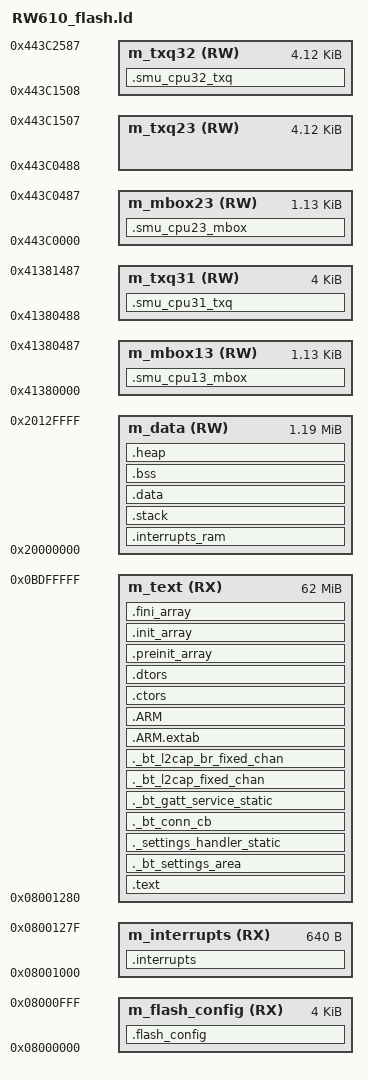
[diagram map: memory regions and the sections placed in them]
/*
** ###################################################################
**     Processors:          RW612ETA2I
**                          RW612HNA2I
**                          RW612UKA2I
**
**     Compiler:            GNU C Compiler
**     Reference manual:    MIMXRW685 User manual Rev. 0.95 11 November 2019
**     Version:             rev. 1.0, 2021-03-16
**     Build:               b220521
**
**     Abstract:
**         Linker file for the GNU C Compiler
**
**     Copyright 2016 Freescale Semiconductor, Inc.
**     Copyright 2016-2024 NXP
**     All rights reserved.
**
**     SPDX-License-Identifier: BSD-3-Clause
**
**     http:                 www.nxp.com
**     mail:                 support@nxp.com
**
** ###################################################################
*/



/* Entry Point */
ENTRY(Reset_Handler)

HEAP_SIZE  = DEFINED(__heap_size__)  ? __heap_size__  : 0x0400;
STACK_SIZE = DEFINED(__stack_size__) ? __stack_size__ : 0x0400;
M_VECTOR_RAM_SIZE = DEFINED(__ram_vector_table__) ? 0x00000280 : 0;

LITTLEFS_REGION_SIZE = 0x00200000;

m_text_start         = 0x08001280;
m_text_size          = 0x03FFED80 - LITTLEFS_REGION_SIZE;

/* Specify the memory areas */
MEMORY
{
  m_flash_config        (RX)  : ORIGIN = 0x08000000, LENGTH = 0x00001000
  m_interrupts          (RX)  : ORIGIN = 0x08001000, LENGTH = 0x00000280
  m_text                (RX)  : ORIGIN = m_text_start, LENGTH = m_text_size
  m_data                (RW)  : ORIGIN = 0x20000000, LENGTH = 0x00130000
  m_mbox13              (RW) : ORIGIN = 0x41380000, LENGTH = 0x00000488
  m_txq31               (RW) : ORIGIN = 0x41380488, LENGTH = 0x00001000
  m_mbox23              (RW) : ORIGIN = 0x443C0000, LENGTH = 0x00000488
  m_txq23               (RW) : ORIGIN = 0x443C0488, LENGTH = 0x00001080
  m_txq32               (RW) : ORIGIN = 0x443C1508, LENGTH = 0x00001080
}

/* NOTE: The last LITTLEFS_REGION_SIZE Flash( in range (m_text_start + m_text_size) ~ (m_text_start + m_text_size + LITTLEFS_REGION_SIZE -1)) is reserved for litteFS data */

/*** littleFS configuration Start ***/
EDGEFAST_BT_LITTLEFS_STORAGE_START_ADDRESS = m_text_start + m_text_size;
EDGEFAST_BT_LITTLEFS_STORAGE_SECTOR_SIZE   = 0x1000;  /* 4k flash sector size */
EDGEFAST_BT_LITTLEFS_STORAGE_MAX_SECTORS   = LITTLEFS_REGION_SIZE / EDGEFAST_BT_LITTLEFS_STORAGE_SECTOR_SIZE;
/*** littleFS configuration End ***/

/* Define output sections */
SECTIONS
{
  .flash_config :
  {
    . = ALIGN(4);
    FILL(0xFF)
    . = 0x400;
    __FLASH_BASE = .;
    KEEP(* (.flash_conf))     /* flash config section */
    . = 0x1000;
  } > m_flash_config

  /* The startup code goes first into internal ram */
  .interrupts :
  {
    . = ALIGN(4);
    __VECTOR_TABLE = .;
    __Vectors = .;
    KEEP(*(.isr_vector))     /* Startup code */
    FILL(0x00)
    . = 0x280;
  } > m_interrupts

  /* The program code and other data goes into internal ram */
  .text :
  {
    . = ALIGN(4);
    *(EXCLUDE_FILE(
        /* Exclude flash and frequently executed functions from XIP */
        */fsl_adapter_flexspi_nor_flash.c.obj
        */mflash_drv.c.obj
        */fsl_flexspi.c.obj
    ) .text)                 /* .text sections (code) */
    *(EXCLUDE_FILE(
        /* Exclude flash and frequently executed functions from XIP */
        */fsl_adapter_flexspi_nor_flash.c.obj
        */mflash_drv.c.obj
        */fsl_flexspi.c.obj
    ) .text*)                /* .text* sections (code) */
    *(.rodata)               /* .rodata sections (constants, strings, etc.) */
    *(.rodata*)              /* .rodata* sections (constants, strings, etc.) */
    *(.glue_7)               /* glue arm to thumb code */
    *(.glue_7t)              /* glue thumb to arm code */
    *(.eh_frame)
    KEEP (*(.init))
    KEEP (*(.fini))
    . = ALIGN(4);
  } > m_text

  ._bt_settings_area :
  {
    . = ALIGN(4);
    _bt_settings_start = .;
    KEEP(*(SORT(._bt_settings.static.*)))
    _bt_settings_end = .;
    . = ALIGN(4);
  } > m_text

  ._settings_handler_static :
  {
    . = ALIGN(4);
    _settings_handler_static_list_start = .;
    KEEP(*(SORT(._settings_handler_static.static.*)))
    _settings_handler_static_list_end = .;
    . = ALIGN(4);
  } > m_text

  ._bt_conn_cb :
  {
    . = ALIGN(4);
    _bt_conn_cb_list_start = .;
    KEEP(*(SORT(._bt_conn_cb.static.*)))
    _bt_conn_cb_list_end = .;
    . = ALIGN(4);
  } > m_text

  ._bt_gatt_service_static :
  {
    . = ALIGN(4);
    _bt_gatt_service_static_list_start = .;
    KEEP(*(SORT(._bt_gatt_service_static.static.*)))
    _bt_gatt_service_static_list_end = .;
    . = ALIGN(4);
  } > m_text

  ._bt_l2cap_fixed_chan :
  {
    . = ALIGN(4);
    _bt_l2cap_fixed_chan_list_start = .;
    KEEP(*(SORT(._bt_l2cap_fixed_chan.static.*)))
    _bt_l2cap_fixed_chan_list_end = .;
    . = ALIGN(4);
  } > m_text

  ._bt_l2cap_br_fixed_chan :
  {
    . = ALIGN(4);
    _bt_l2cap_br_fixed_chan_list_start = .;
    KEEP(*(SORT(._bt_l2cap_br_fixed_chan.static.*)))
    _bt_l2cap_br_fixed_chan_list_end = .;
    . = ALIGN(4);
  } > m_text

  .ARM.extab :
  {
    *(.ARM.extab* .gnu.linkonce.armextab.*)
  } > m_text

  .ARM :
  {
    __exidx_start = .;
    *(.ARM.exidx*)
    __exidx_end = .;
  } > m_text

 .ctors :
  {
    __CTOR_LIST__ = .;
    /* gcc uses crtbegin.o to find the start of
       the constructors, so we make sure it is
       first.  Because this is a wildcard, it
       doesn't matter if the user does not
       actually link against crtbegin.o; the
       linker won't look for a file to match a
       wildcard.  The wildcard also means that it
       doesn't matter which directory crtbegin.o
       is in.  */
    KEEP (*crtbegin.o(.ctors))
    KEEP (*crtbegin?.o(.ctors))
    /* We don't want to include the .ctor section from
       from the crtend.o file until after the sorted ctors.
       The .ctor section from the crtend file contains the
       end of ctors marker and it must be last */
    KEEP (*(EXCLUDE_FILE(*crtend?.o *crtend.o) .ctors))
    KEEP (*(SORT(.ctors.*)))
    KEEP (*(.ctors))
    __CTOR_END__ = .;
  } > m_text

  .dtors :
  {
    __DTOR_LIST__ = .;
    KEEP (*crtbegin.o(.dtors))
    KEEP (*crtbegin?.o(.dtors))
    KEEP (*(EXCLUDE_FILE(*crtend?.o *crtend.o) .dtors))
    KEEP (*(SORT(.dtors.*)))
    KEEP (*(.dtors))
    __DTOR_END__ = .;
  } > m_text

  .preinit_array :
  {
    PROVIDE_HIDDEN (__preinit_array_start = .);
    KEEP (*(.preinit_array*))
    PROVIDE_HIDDEN (__preinit_array_end = .);
  } > m_text

  .init_array :
  {
    PROVIDE_HIDDEN (__init_array_start = .);
    KEEP (*(SORT(.init_array.*)))
    KEEP (*(.init_array*))
    PROVIDE_HIDDEN (__init_array_end = .);
  } > m_text

  .fini_array :
  {
    PROVIDE_HIDDEN (__fini_array_start = .);
    KEEP (*(SORT(.fini_array.*)))
    KEEP (*(.fini_array*))
    PROVIDE_HIDDEN (__fini_array_end = .);
  } > m_text

  __etext = .;    /* define a global symbol at end of code */
  __DATA_ROM = .; /* Symbol is used by startup for data initialization */

  .interrupts_ram :
  {
    . = ALIGN(4);
    __VECTOR_RAM__ = .;
    __interrupts_ram_start__ = .; /* Create a global symbol at data start */
    *(.m_interrupts_ram)     /* This is a user defined section */
    . += M_VECTOR_RAM_SIZE;
    . = ALIGN(4);
    __interrupts_ram_end__ = .; /* Define a global symbol at data end */
  } > m_data

  __VECTOR_RAM = DEFINED(__ram_vector_table__) ? __VECTOR_RAM__ : ORIGIN(m_interrupts);
  __RAM_VECTOR_TABLE_SIZE_BYTES = DEFINED(__ram_vector_table__) ? (__interrupts_ram_end__ - __interrupts_ram_start__) : 0x0;

  .stack :
  {
    . = ALIGN(8);
    __StackLimit = .;
    . += STACK_SIZE;
    __StackTop = .;
  } > m_data

  PROVIDE(__stack = __StackTop);

  .data : AT(__DATA_ROM)
  {
    . = ALIGN(4);
    __DATA_RAM = .;
    __data_start__ = .;      /* create a global symbol at data start */
    *(CodeQuickAccess)       /* CodeQuickAccess sections */
    *(DataQuickAccess)       /* DataQuickAccess sections */
    *(m_usb_dma_init_data)
    /* Explicit placement of flash and frequently executed functions in RAM */
    */fsl_adapter_flexspi_nor_flash.c.obj
    */mflash_drv.c.obj
    */fsl_flexspi.c.obj
    *(.data)                 /* .data sections */
    *(.data*)                /* .data* sections */
    KEEP(*(.jcr*))
    . = ALIGN(4);
    _k_mem_slab_list_start = .;
    KEEP(*(SORT(._k_mem_slab*)))
    _k_mem_slab_list_end = .;
    . = ALIGN(4);
    _net_buf_pool_list = .;
    KEEP(*(SORT(._net_buf_pool*)))
    . = ALIGN(4);
    __data_end__ = .;        /* define a global symbol at data end */
  } > m_data

  __DATA_END = __DATA_ROM + (__data_end__ - __data_start__);
  text_end = ORIGIN(m_text) + LENGTH(m_text);
  ASSERT(__DATA_END <= text_end, "region m_text overflowed with text and data")
  _image_size = __DATA_END - __VECTOR_TABLE;

  /* Uninitialized data section */
  .bss :
  {
    /* This is used by the startup in order to initialize the .bss section */
    . = ALIGN(4);
    __START_BSS = .;
    __bss_start__ = .;
    *(.bss)
    *(.bss*)
    *(COMMON)
    . = ALIGN(4);
    __bss_end__ = .;
    __END_BSS = .;
  } > m_data

  .heap :
  {
    . = ALIGN(8);
    __end__ = .;
    PROVIDE(end = .);
    __HeapBase = .;
    . += HEAP_SIZE;
    __HeapLimit = .;
    __heap_limit = .; /* Add for _sbrk */
  } > m_data

  .ARM.attributes 0 : { *(.ARM.attributes) }

  .smu_cpu13_mbox (NOLOAD) :
  {
    . = ALIGN(4);
    *(.smu_cpu13_mbox)
    KEEP (*(.smu_cpu13_mbox))
    . = ALIGN(4);
  } > m_mbox13

  .smu_cpu31_txq (NOLOAD) :
  {
    . = ALIGN(4);
    *(.smu_cpu31_txq)
    KEEP (*(.smu_cpu31_txq))
    . = ALIGN(4);
  } > m_txq31

  .smu_cpu23_mbox (NOLOAD) :
  {
    . = ALIGN(4);
    *(.smu_cpu23_mbox)
    KEEP (*(.smu_cpu23_mbox))
    . = ALIGN(4);
  } > m_mbox23

  .smu_cpu32_txq (NOLOAD) :
  {
    . = ALIGN(4);
    *(.smu_cpu32_txq)
    KEEP (*(.smu_cpu32_txq))
    . = ALIGN(4);
  } > m_txq32
}

